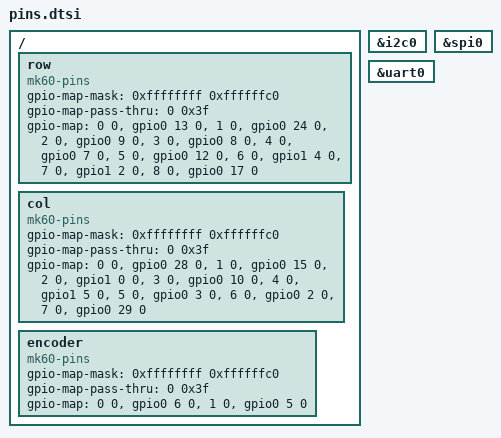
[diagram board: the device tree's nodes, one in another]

/ {
	row: row {
		compatible = "mk60-pins";
		#gpio-cells = <2>;
		gpio-map-mask = <0xffffffff 0xffffffc0>;
		gpio-map-pass-thru = <0 0x3f>;
		gpio-map
			= <0 0 &gpio0 13 0>
			, <1 0 &gpio0 24 0>
			, <2 0 &gpio0 9  0>
			, <3 0 &gpio0 8  0>
			, <4 0 &gpio0 7  0>
			, <5 0 &gpio0 12 0>
			, <6 0 &gpio1 4  0>
			, <7 0 &gpio1 2  0>
			, <8 0 &gpio0 17 0>
			;
	};

	col: col {
		compatible = "mk60-pins";
		#gpio-cells = <2>;
		gpio-map-mask = <0xffffffff 0xffffffc0>;
		gpio-map-pass-thru = <0 0x3f>;
		gpio-map
			= <0 0 &gpio0 28 0>
			, <1 0 &gpio0 15 0>
			, <2 0 &gpio1 0  0>
			, <3 0 &gpio0 10 0>
			, <4 0 &gpio1 5  0>
			, <5 0 &gpio0 3  0>
			, <6 0 &gpio0 2  0>
			, <7 0 &gpio0 29 0>
			;
	};

	encoder: encoder {
		compatible = "mk60-pins";
		#gpio-cells = <2>;
		gpio-map-mask = <0xffffffff 0xffffffc0>;
		gpio-map-pass-thru = <0 0x3f>;
		gpio-map
			= <0 0 &gpio0 6 0>
			, <1 0 &gpio0 5 0>
			;
	};
};


pro_micro_i2c: &i2c0 {};
pro_micro_spi: &spi0 {};
pro_micro_serial: &uart0 {};
